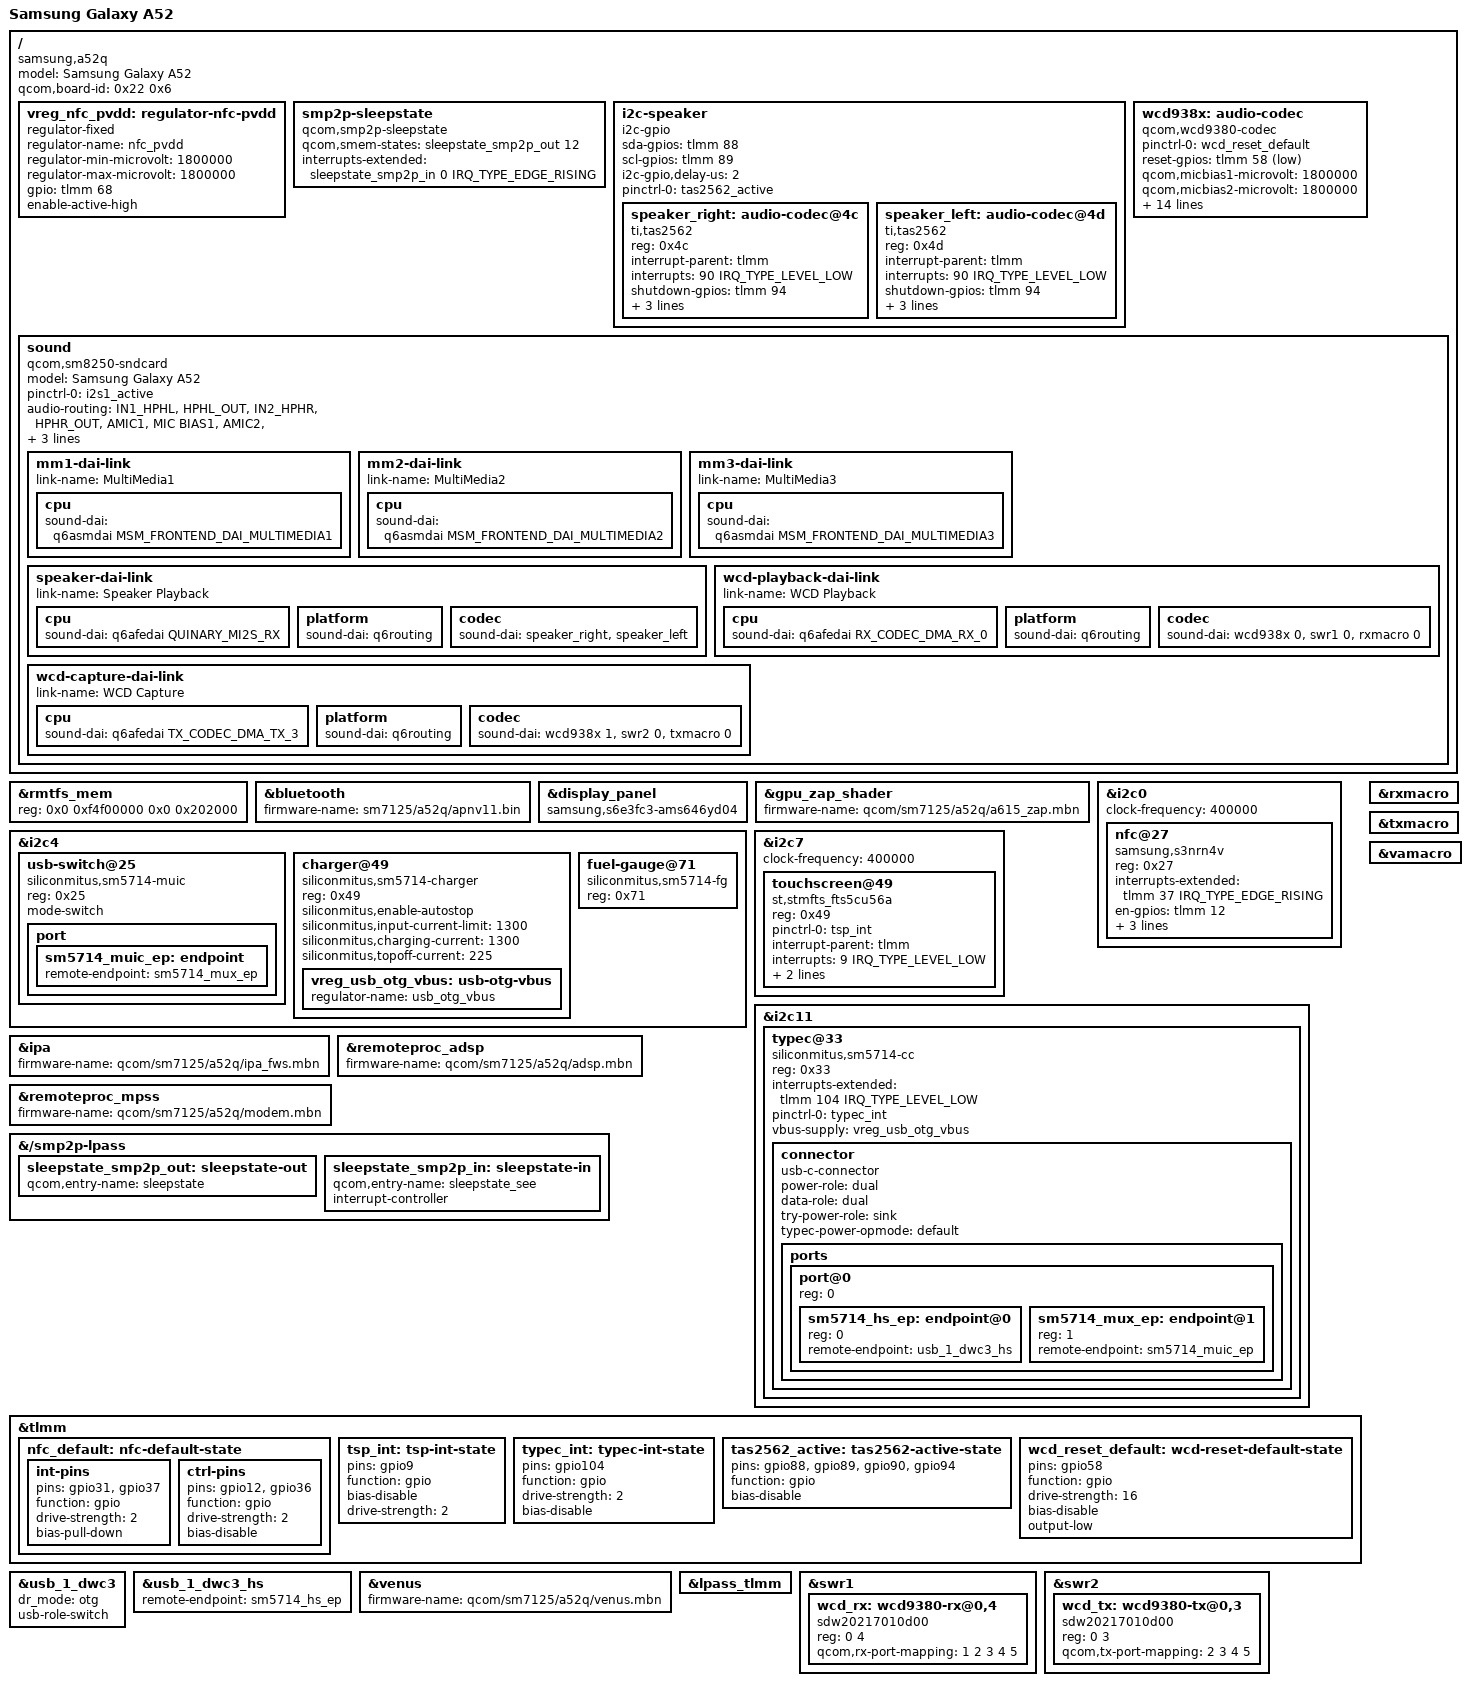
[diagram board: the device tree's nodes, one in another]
// SPDX-License-Identifier: GPL-2.0
/*
 * SM7125 Samsung Galaxy A52 (a52q) specific device tree source
 *
 * Copyright (c) 2026, Erikas Bitovtas. All rights reserved.
 */

/dts-v1/;

#include <dt-bindings/interrupt-controller/irq.h>
#include <dt-bindings/sound/qcom,q6afe.h>
#include <dt-bindings/sound/qcom,q6asm.h>
#include <dt-bindings/sound/qcom,q6dsp-lpass-ports.h>
#include "sm7125-samsung-common.dtsi"

/ {
	model = "Samsung Galaxy A52";
	compatible = "samsung,a52q", "qcom,sm7125";
	qcom,board-id = <0x22 0x6>;

	vreg_nfc_pvdd: regulator-nfc-pvdd {
		compatible = "regulator-fixed";
		regulator-name = "nfc_pvdd";
		regulator-min-microvolt = <1800000>;
		regulator-max-microvolt = <1800000>;
		gpio = <&tlmm 68 GPIO_ACTIVE_HIGH>;
		enable-active-high;
	};

	/*
	 * Publish the AP sleep state to the ADSP sensor framework (SEE).
	 * Without it the ADSP faults on system suspend, see
	 * drivers/soc/qcom/smp2p_sleepstate.c.
	 */
	smp2p-sleepstate {
		compatible = "qcom,smp2p-sleepstate";
		qcom,smem-states = <&sleepstate_smp2p_out 12>;
		interrupts-extended = <&sleepstate_smp2p_in 0 IRQ_TYPE_EDGE_RISING>;
	};

	/* Stereo speaker amplifiers on a bit-banged I2C bus (SCL stretch) */
	i2c-speaker {
		compatible = "i2c-gpio";
		sda-gpios = <&tlmm 88 (GPIO_ACTIVE_HIGH | GPIO_OPEN_DRAIN)>;
		scl-gpios = <&tlmm 89 (GPIO_ACTIVE_HIGH | GPIO_OPEN_DRAIN)>;
		i2c-gpio,delay-us = <2>;
		pinctrl-names = "default";
		pinctrl-0 = <&tas2562_active>;
		#address-cells = <1>;
		#size-cells = <0>;

		speaker_right: audio-codec@4c {
			compatible = "ti,tas2562";
			reg = <0x4c>;
			interrupt-parent = <&tlmm>;
			interrupts = <90 IRQ_TYPE_LEVEL_LOW>;
			shutdown-gpios = <&tlmm 94 GPIO_ACTIVE_HIGH>;
			ti,imon-slot-no = <0>;
			ti,rx-slot-width = <16>;
			sound-name-prefix = "Right";
			#sound-dai-cells = <0>;
		};

		speaker_left: audio-codec@4d {
			compatible = "ti,tas2562";
			reg = <0x4d>;
			interrupt-parent = <&tlmm>;
			interrupts = <90 IRQ_TYPE_LEVEL_LOW>;
			shutdown-gpios = <&tlmm 94 GPIO_ACTIVE_HIGH>;
			ti,imon-slot-no = <0>;
			ti,rx-slot-width = <16>;
			sound-name-prefix = "Left";
			#sound-dai-cells = <0>;
		};
	};

	wcd938x: audio-codec {
		compatible = "qcom,wcd9380-codec";

		pinctrl-names = "default";
		pinctrl-0 = <&wcd_reset_default>;

		reset-gpios = <&tlmm 58 GPIO_ACTIVE_LOW>;

		qcom,micbias1-microvolt = <1800000>;
		qcom,micbias2-microvolt = <1800000>;
		qcom,micbias3-microvolt = <1800000>;
		qcom,micbias4-microvolt = <1800000>;
		qcom,mbhc-buttons-vthreshold-microvolt = <75000 150000 237000 500000
							  500000 500000 500000 500000>;
		qcom,mbhc-headset-vthreshold-microvolt = <1700000>;
		qcom,mbhc-headphone-vthreshold-microvolt = <50000>;
		qcom,rx-device = <&wcd_rx>;
		qcom,tx-device = <&wcd_tx>;

		vdd-buck-supply = <&vreg_l15a_1p8>;
		vdd-rxtx-supply = <&vreg_l10a_1p8>;
		vdd-io-supply = <&vreg_l10a_1p8>;
		vdd-mic-bias-supply = <&vreg_bob>;

		#sound-dai-cells = <1>;
	};
};

&rmtfs_mem {
	reg = <0x0 0xf4f00000 0x0 0x202000>;
};

&bluetooth {
	firmware-name = "sm7125/a52q/apnv11.bin";
};

&display_panel {
	compatible = "samsung,s6e3fc3-ams646yd04", "samsung,s6e3fc3";

	status = "okay";
};

&gpu_zap_shader {
	firmware-name = "qcom/sm7125/a52q/a615_zap.mbn";
};

&i2c0 {
	clock-frequency = <400000>;
	status = "okay";

	nfc@27 {
		compatible = "samsung,s3nrn4v";
		reg = <0x27>;

		interrupts-extended = <&tlmm 37 IRQ_TYPE_EDGE_RISING>;
		en-gpios = <&tlmm 12 GPIO_ACTIVE_HIGH>;
		wake-gpios = <&tlmm 36 GPIO_ACTIVE_HIGH>;
		pvdd-supply = <&vreg_nfc_pvdd>;

		pinctrl-names = "default";
		pinctrl-0 = <&nfc_default>;
	};
};

&i2c4 {
	status = "okay";

	usb-switch@25 {
		compatible = "siliconmitus,sm5714-muic";
		reg = <0x25>;
		mode-switch;

		port {
			sm5714_muic_ep: endpoint {
				remote-endpoint = <&sm5714_mux_ep>;
			};
		};
	};

	charger@49 {
		compatible = "siliconmitus,sm5714-charger";
		reg = <0x49>;

		siliconmitus,enable-autostop;
		siliconmitus,input-current-limit = <1300>;
		siliconmitus,charging-current = <1300>;
		siliconmitus,topoff-current = <225>;

		vreg_usb_otg_vbus: usb-otg-vbus {
			regulator-name = "usb_otg_vbus";
		};
	};

	fuel-gauge@71 {
		compatible = "siliconmitus,sm5714-fg";
		reg = <0x71>;
	};
};

&i2c7 {
	status = "okay";
	clock-frequency = <400000>;

	touchscreen@49 {
		compatible = "st,stmfts_fts5cu56a";
		reg = <0x49>;

		pinctrl-names = "default";
		pinctrl-0 = <&tsp_int>;

		interrupt-parent = <&tlmm>;
		interrupts = <9 IRQ_TYPE_LEVEL_LOW>;

		vdd-supply = <&vreg_l10a_1p8>;
		avdd-supply = <&vreg_l7c_3p0>;
	};
};

&i2c11 {
	status = "okay";

	typec@33 {
		compatible = "siliconmitus,sm5714-cc";
		reg = <0x33>;
		interrupts-extended = <&tlmm 104 IRQ_TYPE_LEVEL_LOW>;

		pinctrl-names = "default";
		pinctrl-0 = <&typec_int>;

		vbus-supply = <&vreg_usb_otg_vbus>;

		connector {
			compatible = "usb-c-connector";
			power-role = "dual";
			data-role = "dual";
			try-power-role = "sink";
			typec-power-opmode = "default";

			ports {
				#address-cells = <1>;
				#size-cells = <0>;

				port@0 {
					reg = <0>;
					#address-cells = <1>;
					#size-cells = <0>;

					sm5714_hs_ep: endpoint@0 {
						reg = <0>;
						remote-endpoint = <&usb_1_dwc3_hs>;
					};

					sm5714_mux_ep: endpoint@1 {
						reg = <1>;
						remote-endpoint = <&sm5714_muic_ep>;
					};
				};
			};
		};
	};
};

&ipa {
	firmware-name = "qcom/sm7125/a52q/ipa_fws.mbn";

	status = "okay";
};

&remoteproc_adsp {
	firmware-name = "qcom/sm7125/a52q/adsp.mbn";

	status = "okay";
};

&remoteproc_mpss {
	firmware-name = "qcom/sm7125/a52q/modem.mbn";

	status = "okay";
};

/* SMP2P sleepstate entries on the ADSP edge, consumed by smp2p-sleepstate. */
&{/smp2p-lpass} {
	sleepstate_smp2p_out: sleepstate-out {
		qcom,entry-name = "sleepstate";
		#qcom,smem-state-cells = <1>;
	};

	sleepstate_smp2p_in: sleepstate-in {
		qcom,entry-name = "sleepstate_see";
		interrupt-controller;
		#interrupt-cells = <2>;
	};
};

&tlmm {
	nfc_default: nfc-default-state {
		int-pins {
			pins = "gpio31", "gpio37";
			function = "gpio";
			drive-strength = <2>;
			bias-pull-down;
		};

		ctrl-pins {
			pins = "gpio12", "gpio36";
			function = "gpio";
			drive-strength = <2>;
			bias-disable;
		};
	};

	tsp_int: tsp-int-state {
		pins = "gpio9";
		function = "gpio";
		bias-disable;
		drive-strength = <2>;
	};

	typec_int: typec-int-state {
		pins = "gpio104";
		function = "gpio";
		drive-strength = <2>;
		bias-disable;
	};
};

&usb_1_dwc3 {
	dr_mode = "otg";
	usb-role-switch;
};

&usb_1_dwc3_hs {
	remote-endpoint = <&sm5714_hs_ep>;
};

&venus {
	firmware-name = "qcom/sm7125/a52q/venus.mbn";
};

&lpass_tlmm {
	status = "okay";
};

&rxmacro {
	status = "okay";
};

/ {
	sound {
		compatible = "qcom,sm8250-sndcard";
		model = "Samsung Galaxy A52";

		pinctrl-names = "default";
		pinctrl-0 = <&i2s1_active>;

		audio-routing = "IN1_HPHL", "HPHL_OUT",
				"IN2_HPHR", "HPHR_OUT",
				"AMIC1", "MIC BIAS1",
				"AMIC2", "MIC BIAS2",
				"AMIC4", "MIC BIAS3",
				"TX SWR_ADC0", "ADC1_OUTPUT",
				"TX SWR_ADC1", "ADC2_OUTPUT",
				"TX SWR_ADC3", "ADC4_OUTPUT";

		mm1-dai-link {
			link-name = "MultiMedia1";

			cpu {
				sound-dai = <&q6asmdai MSM_FRONTEND_DAI_MULTIMEDIA1>;
			};
		};

		mm2-dai-link {
			link-name = "MultiMedia2";

			cpu {
				sound-dai = <&q6asmdai MSM_FRONTEND_DAI_MULTIMEDIA2>;
			};
		};

		mm3-dai-link {
			link-name = "MultiMedia3";

			cpu {
				sound-dai = <&q6asmdai MSM_FRONTEND_DAI_MULTIMEDIA3>;
			};
		};

		speaker-dai-link {
			link-name = "Speaker Playback";

			cpu {
				sound-dai = <&q6afedai QUINARY_MI2S_RX>;
			};

			platform {
				sound-dai = <&q6routing>;
			};

			codec {
				sound-dai = <&speaker_right>, <&speaker_left>;
			};
		};

		wcd-playback-dai-link {
			link-name = "WCD Playback";

			cpu {
				sound-dai = <&q6afedai RX_CODEC_DMA_RX_0>;
			};

			platform {
				sound-dai = <&q6routing>;
			};

			codec {
				sound-dai = <&wcd938x 0>, <&swr1 0>, <&rxmacro 0>;
			};
		};

		wcd-capture-dai-link {
			link-name = "WCD Capture";

			cpu {
				sound-dai = <&q6afedai TX_CODEC_DMA_TX_3>;
			};

			platform {
				sound-dai = <&q6routing>;
			};

			codec {
				sound-dai = <&wcd938x 1>, <&swr2 0>, <&txmacro 0>;
			};
		};
	};
};

&swr1 {
	status = "okay";

	/* WCD9380 RX */
	wcd_rx: wcd9380-rx@0,4 {
		compatible = "sdw20217010d00";
		reg = <0 4>;
		qcom,rx-port-mapping = <1 2 3 4 5>;
	};
};

&swr2 {
	status = "okay";

	/* WCD9380 TX */
	wcd_tx: wcd9380-tx@0,3 {
		compatible = "sdw20217010d00";
		reg = <0 3>;
		qcom,tx-port-mapping = <2 3 4 5>;
	};
};

&tlmm {
	tas2562_active: tas2562-active-state {
		/* SDA, SCL, INT, EN */
		pins = "gpio88", "gpio89", "gpio90", "gpio94";
		function = "gpio";
		bias-disable;
	};

	wcd_reset_default: wcd-reset-default-state {
		pins = "gpio58";
		function = "gpio";
		drive-strength = <16>;
		bias-disable;
		output-low;
	};
};

&txmacro {
	status = "okay";
};

&vamacro {
	status = "okay";
};
